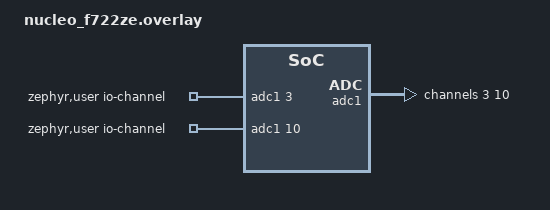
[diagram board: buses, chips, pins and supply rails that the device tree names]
/*
 * SPDX-License-Identifier: Apache-2.0
 *
 * Copyright (c) 2023 Evan Perry Grove
 */

/ {
	zephyr,user {
		io-channels = <&adc1 3>, <&adc1 10>;
	};
};

&adc1 {
	#address-cells = <1>;
	#size-cells = <0>;

	channel@3 {
		reg = <3>;
		zephyr,gain = "ADC_GAIN_1";
		zephyr,reference = "ADC_REF_INTERNAL";
		zephyr,acquisition-time = <ADC_ACQ_TIME_DEFAULT>;
		zephyr,resolution = <12>;
	};

	channel@a {
		reg = <10>;
		zephyr,gain = "ADC_GAIN_1";
		zephyr,reference = "ADC_REF_INTERNAL";
		zephyr,acquisition-time = <ADC_ACQ_TIME_DEFAULT>;
		zephyr,resolution = <12>;
	};
};
